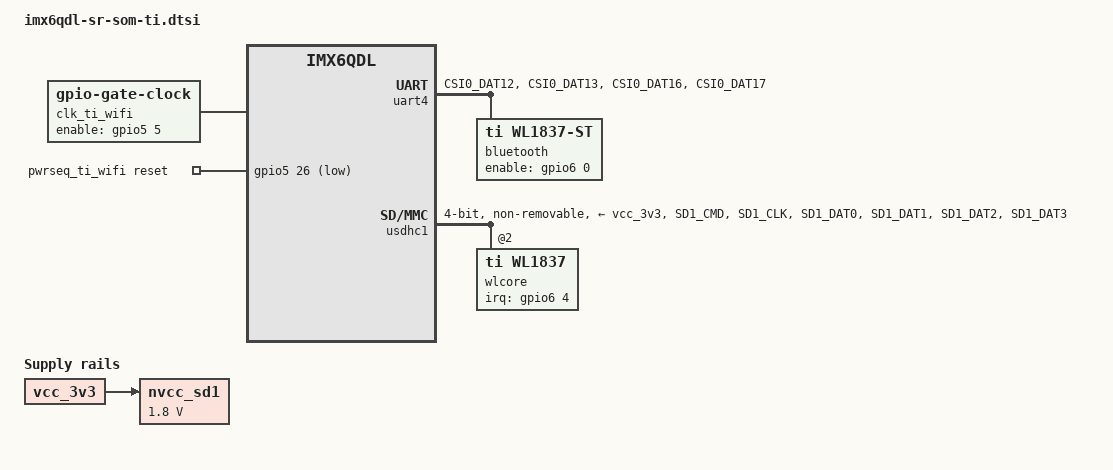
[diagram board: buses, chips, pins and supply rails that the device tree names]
#include <dt-bindings/gpio/gpio.h>
/ {
	nvcc_sd1: regulator-nvcc-sd1 {
		compatible = "regulator-fixed";
		regulator-always-on;
		regulator-name = "nvcc_sd1";
		regulator-min-microvolt = <1800000>;
		regulator-max-microvolt = <1800000>;
		vin-supply = <&vcc_3v3>;
	};
	clk_ti_wifi: ti-wifi-clock {
		compatible = "gpio-gate-clock";
		#clock-cells = <0>;
		clock-frequency = <32768>;
		pinctrl-names = "default";
		pinctrl-0 = <&pinctrl_microsom_ti_clk>;
		enable-gpios = <&gpio5 5 GPIO_ACTIVE_HIGH>;
	};
	pwrseq_ti_wifi: ti-wifi-pwrseq {
		compatible = "mmc-pwrseq-simple";
		pinctrl-names = "default";
		pinctrl-0 = <&pinctrl_microsom_ti_wifi_en>;
		reset-gpios = <&gpio5 26 GPIO_ACTIVE_LOW>;
		post-power-on-delay-ms = <200>;
		clocks = <&clk_ti_wifi>;
		clock-names = "ext_clock";
	};
};
&iomuxc {
	microsom {
		pinctrl_microsom_ti_bt: microsom-ti-bt {
			fsl,pins = <
				MX6QDL_PAD_CSI0_DAT14__GPIO6_IO00	0x40013070
			>;
		};
		pinctrl_microsom_ti_clk: microsom-ti-clk {
			fsl,pins = <
				MX6QDL_PAD_GPIO_8__XTALOSC_REF_CLK_32K	0x1b0b0
				MX6QDL_PAD_DISP0_DAT11__GPIO5_IO05 0x40013070
			>;
		};
		pinctrl_microsom_ti_wifi_en: microsom-ti-wifi-en {
			fsl,pins = <
				MX6QDL_PAD_CSI0_DAT8__GPIO5_IO26	0x40013070
			>;
		};
		pinctrl_microsom_ti_wifi_irq: microsom-ti-wifi-irq {
			fsl,pins = <
				MX6QDL_PAD_CSI0_DAT18__GPIO6_IO04	0x40013070
			>;
		};
		pinctrl_microsom_uart4: microsom-uart4 {
			fsl,pins = <
				MX6QDL_PAD_CSI0_DAT12__UART4_TX_DATA 0x1b0b1
				MX6QDL_PAD_CSI0_DAT13__UART4_RX_DATA 0x1b0b1
				MX6QDL_PAD_CSI0_DAT16__UART4_RTS_B 0x1b0b1
				MX6QDL_PAD_CSI0_DAT17__UART4_CTS_B 0x1b0b1
			>;
		};
		pinctrl_microsom_usdhc1: microsom-usdhc1 {
			fsl,pins = <
				MX6QDL_PAD_SD1_CMD__SD1_CMD    0x17059
				MX6QDL_PAD_SD1_CLK__SD1_CLK    0x10059
				MX6QDL_PAD_SD1_DAT0__SD1_DATA0 0x17059
				MX6QDL_PAD_SD1_DAT1__SD1_DATA1 0x17059
				MX6QDL_PAD_SD1_DAT2__SD1_DATA2 0x17059
				MX6QDL_PAD_SD1_DAT3__SD1_DATA3 0x17059
			>;
		};
	};
};
&uart4 {
	pinctrl-names = "default";
	pinctrl-0 = <&pinctrl_microsom_uart4>;
	uart-has-rtscts;
	status = "okay";
	bluetooth {
		compatible = "ti,wl1837-st";
		clocks = <&clk_ti_wifi>;
		clock-names = "ext_clock";
		enable-gpios = <&gpio6 0 GPIO_ACTIVE_HIGH>;
		pinctrl-names = "default";
		pinctrl-0 = <&pinctrl_microsom_ti_bt>;
	};
};
&usdhc1 {
	pinctrl-names = "default";
	pinctrl-0 = <&pinctrl_microsom_usdhc1>;
	bus-width = <4>;
	keep-power-in-suspend;
	mmc-pwrseq = <&pwrseq_ti_wifi>;
	cap-power-off-card;
	non-removable;
	vmmc-supply = <&vcc_3v3>;
	status = "okay";
	#address-cells = <1>;
	#size-cells = <0>;
	wlcore@2 {
		compatible = "ti,wl1837";
		reg = <2>;
		interrupts-extended = <&gpio6 4 IRQ_TYPE_LEVEL_HIGH>;
		pinctrl-names = "default";
		pinctrl-0 = <&pinctrl_microsom_ti_wifi_irq>;
	};
};
